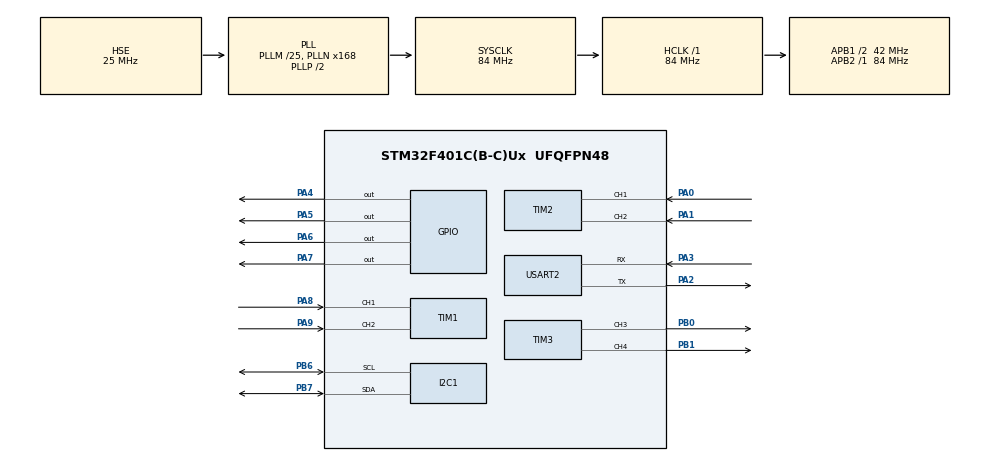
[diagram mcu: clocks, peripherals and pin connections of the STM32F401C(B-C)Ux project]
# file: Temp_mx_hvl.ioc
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Mcu.Family=STM32F4
Mcu.Name=STM32F401C(B-C)Ux
Mcu.Package=UFQFPN48
NVIC.PriorityGroup=NVIC_PRIORITYGROUP_2
NVIC.TIM4_IRQn=true\:2\:1\:true\:false\:true\:true\:true
NVIC.USART2_IRQn=true\:1\:1\:true\:false\:true\:true\:true
PA0-WKUP.Signal=S_TIM2_CH1_ETR
PA1.Signal=S_TIM2_CH2
PA13.Mode=Serial_Wire
PA13.Signal=SYS_JTMS-SWDIO
PA14.Mode=Serial_Wire
PA14.Signal=SYS_JTCK-SWCLK
PA2.Mode=Asynchronous
PA2.Signal=USART2_TX
PA3.Mode=Asynchronous
PA3.Signal=USART2_RX
PA4.GPIO_PuPd=GPIO_PULLUP
PA4.GPIO_Speed=GPIO_SPEED_FREQ_HIGH
PA4.Signal=GPIO_Output
PA5.GPIO_PuPd=GPIO_PULLUP
PA5.GPIO_Speed=GPIO_SPEED_FREQ_HIGH
PA5.Signal=GPIO_Output
PA6.GPIO_PuPd=GPIO_PULLUP
PA6.GPIO_Speed=GPIO_SPEED_FREQ_HIGH
PA6.Signal=GPIO_Output
PA7.GPIO_PuPd=GPIO_PULLUP
PA7.GPIO_Speed=GPIO_SPEED_FREQ_HIGH
PA7.Signal=GPIO_Output
PA8.Signal=S_TIM1_CH1
PA9.Signal=S_TIM1_CH2
PB0.Signal=S_TIM3_CH3
PB1.Signal=S_TIM3_CH4
PB6.Mode=I2C
PB6.Signal=I2C1_SCL
PB7.Mode=I2C
PB7.Signal=I2C1_SDA
PC14-OSC32_IN.Mode=LSE-External-Oscillator
PC14-OSC32_IN.Signal=RCC_OSC32_IN
PC15-OSC32_OUT.Mode=LSE-External-Oscillator
PC15-OSC32_OUT.Signal=RCC_OSC32_OUT
PH0\ -\ OSC_IN.Mode=HSE-External-Oscillator
PH0\ -\ OSC_IN.Signal=RCC_OSC_IN
PH1\ -\ OSC_OUT.Mode=HSE-External-Oscillator
PH1\ -\ OSC_OUT.Signal=RCC_OSC_OUT
ProjectManager.HeapSize=0x200
ProjectManager.StackSize=0x400
ProjectManager.TargetToolchain=MDK-ARM V5
RCC.48MHZClocksFreq_Value=42000000
RCC.AHBFreq_Value=84000000
RCC.APB1CLKDivider=RCC_HCLK_DIV2
RCC.APB1Freq_Value=42000000
RCC.APB1TimFreq_Value=84000000
RCC.APB2Freq_Value=84000000
RCC.APB2TimFreq_Value=84000000
RCC.CortexFreq_Value=84000000
RCC.HCLKFreq_Value=84000000
RCC.HSE_VALUE=25000000
RCC.HSI_VALUE=16000000
RCC.PLLM=25
RCC.PLLN=168
RCC.PLLSourceVirtual=RCC_PLLSOURCE_HSE
RCC.SYSCLKFreq_VALUE=84000000
RCC.SYSCLKSource=RCC_SYSCLKSOURCE_PLLCLK
RCC.VCOOutputFreq_Value=168000000
SH.S_TIM1_CH1.0=TIM1_CH1,Encoder_Interface
SH.S_TIM1_CH2.0=TIM1_CH2,Encoder_Interface
SH.S_TIM2_CH1_ETR.0=TIM2_CH1,Encoder_Interface
SH.S_TIM2_CH2.0=TIM2_CH2,Encoder_Interface
SH.S_TIM3_CH3.0=TIM3_CH3,PWM Generation3 CH3
SH.S_TIM3_CH4.0=TIM3_CH4,PWM Generation4 CH4
TIM3.Channel-PWM\ Generation3\ CH3=TIM_CHANNEL_3
TIM3.Channel-PWM\ Generation4\ CH4=TIM_CHANNEL_4
TIM4.AutoReloadPreload=TIM_AUTORELOAD_PRELOAD_ENABLE
TIM4.Period=100
TIM4.Prescaler=84
USART2.VirtualMode=VM_ASYNC
VP_TIM10_VS_ClockSourceINT.Mode=Enable_Timer
VP_TIM4_VS_ClockSourceINT.Mode=Internal
board=custom

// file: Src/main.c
/* USER CODE BEGIN Header */
/**
  ******************************************************************************
  * @file           : main.c
  * @brief          : Main program body
  ******************************************************************************
  * @attention
  *
  * <h2><center>&copy; Copyright (c) 2019 STMicroelectronics.
  * All rights reserved.</center></h2>
  *
  * This software component is licensed by ST under BSD 3-Clause license,
  * the "License"; You may not use this file except in compliance with the
  * License. You may obtain a copy of the License at:
  *                        opensource.org/licenses/BSD-3-Clause
  *
  ******************************************************************************
  */
/* USER CODE END Header */

#include "main.h"

/* USER CODE BEGIN PD */
#define USE_HAL_TIM_REGISTER_CALLBACKS 1
/* USER CODE END PD */

I2C_HandleTypeDef hi2c1;

TIM_HandleTypeDef htim1;
TIM_HandleTypeDef htim2;
TIM_HandleTypeDef htim3;
TIM_HandleTypeDef htim4;
TIM_HandleTypeDef htim10;

UART_HandleTypeDef huart2;

void SystemClock_Config(void);
static void MX_GPIO_Init(void);
void MX_TIM4_Init(void);
void MX_USART2_UART_Init(void);
static void MX_I2C1_Init(void);
static void MX_TIM1_Init(void);
static void MX_TIM2_Init(void);
static void MX_TIM3_Init(void);
static void MX_TIM10_Init(void);

int main(void)
{

  /* MCU Configuration--------------------------------------------------------*/

  /* Reset of all peripherals, Initializes the Flash interface and the Systick. */
  HAL_Init();

  /* Configure the system clock */
  SystemClock_Config();

  /* Initialize all configured peripherals */
  MX_GPIO_Init();
  MX_TIM4_Init();
  MX_USART2_UART_Init();
  MX_I2C1_Init();
  MX_TIM1_Init();
  MX_TIM2_Init();
  MX_TIM3_Init();
  MX_TIM10_Init();
  /* USER CODE BEGIN 2 */
  __HAL_TIM_ENABLE(&htim4);
  /* USER CODE END 2 */

  /* Infinite loop */
  while (1)
  {

  }
}

void SystemClock_Config(void)
{
  RCC_OscInitTypeDef RCC_OscInitStruct = {0};
  RCC_ClkInitTypeDef RCC_ClkInitStruct = {0};

  /** Configure the main internal regulator output voltage
  */
  __HAL_RCC_PWR_CLK_ENABLE();
  __HAL_PWR_VOLTAGESCALING_CONFIG(PWR_REGULATOR_VOLTAGE_SCALE2);
  /** Initializes the CPU, AHB and APB busses clocks
  */
  RCC_OscInitStruct.OscillatorType = RCC_OSCILLATORTYPE_HSE;
  RCC_OscInitStruct.HSEState = RCC_HSE_ON;
  RCC_OscInitStruct.PLL.PLLState = RCC_PLL_ON;
  RCC_OscInitStruct.PLL.PLLSource = RCC_PLLSOURCE_HSE;
  RCC_OscInitStruct.PLL.PLLM = 25;
  RCC_OscInitStruct.PLL.PLLN = 168;
  RCC_OscInitStruct.PLL.PLLP = RCC_PLLP_DIV2;
  RCC_OscInitStruct.PLL.PLLQ = 4;
  if (HAL_RCC_OscConfig(&RCC_OscInitStruct) != HAL_OK)
  {
    Error_Handler();
  }
  /** Initializes the CPU, AHB and APB busses clocks
  */
  RCC_ClkInitStruct.ClockType = RCC_CLOCKTYPE_HCLK|RCC_CLOCKTYPE_SYSCLK
                              |RCC_CLOCKTYPE_PCLK1|RCC_CLOCKTYPE_PCLK2;
  RCC_ClkInitStruct.SYSCLKSource = RCC_SYSCLKSOURCE_PLLCLK;
  RCC_ClkInitStruct.AHBCLKDivider = RCC_SYSCLK_DIV1;
  RCC_ClkInitStruct.APB1CLKDivider = RCC_HCLK_DIV2;
  RCC_ClkInitStruct.APB2CLKDivider = RCC_HCLK_DIV1;

  if (HAL_RCC_ClockConfig(&RCC_ClkInitStruct, FLASH_LATENCY_2) != HAL_OK)
  {
    Error_Handler();
  }
}

static void MX_I2C1_Init(void)
{

  hi2c1.Instance = I2C1;
  hi2c1.Init.ClockSpeed = 100000;
  hi2c1.Init.DutyCycle = I2C_DUTYCYCLE_2;
  hi2c1.Init.OwnAddress1 = 0;
  hi2c1.Init.AddressingMode = I2C_ADDRESSINGMODE_7BIT;
  hi2c1.Init.DualAddressMode = I2C_DUALADDRESS_DISABLE;
  hi2c1.Init.OwnAddress2 = 0;
  hi2c1.Init.GeneralCallMode = I2C_GENERALCALL_DISABLE;
  hi2c1.Init.NoStretchMode = I2C_NOSTRETCH_DISABLE;
  if (HAL_I2C_Init(&hi2c1) != HAL_OK)
  {
    Error_Handler();
  }

}

static void MX_TIM1_Init(void)
{

  TIM_Encoder_InitTypeDef sConfig = {0};
  TIM_MasterConfigTypeDef sMasterConfig = {0};

  htim1.Instance = TIM1;
  htim1.Init.Prescaler = 0;
  htim1.Init.CounterMode = TIM_COUNTERMODE_UP;
  htim1.Init.Period = 0;
  htim1.Init.ClockDivision = TIM_CLOCKDIVISION_DIV1;
  htim1.Init.RepetitionCounter = 0;
  htim1.Init.AutoReloadPreload = TIM_AUTORELOAD_PRELOAD_DISABLE;
  sConfig.EncoderMode = TIM_ENCODERMODE_TI1;
  sConfig.IC1Polarity = TIM_ICPOLARITY_RISING;
  sConfig.IC1Selection = TIM_ICSELECTION_DIRECTTI;
  sConfig.IC1Prescaler = TIM_ICPSC_DIV1;
  sConfig.IC1Filter = 0;
  sConfig.IC2Polarity = TIM_ICPOLARITY_RISING;
  sConfig.IC2Selection = TIM_ICSELECTION_DIRECTTI;
  sConfig.IC2Prescaler = TIM_ICPSC_DIV1;
  sConfig.IC2Filter = 0;
  if (HAL_TIM_Encoder_Init(&htim1, &sConfig) != HAL_OK)
  {
    Error_Handler();
  }
  sMasterConfig.MasterOutputTrigger = TIM_TRGO_RESET;
  sMasterConfig.MasterSlaveMode = TIM_MASTERSLAVEMODE_DISABLE;
  if (HAL_TIMEx_MasterConfigSynchronization(&htim1, &sMasterConfig) != HAL_OK)
  {
    Error_Handler();
  }

}

static void MX_TIM2_Init(void)
{

  TIM_Encoder_InitTypeDef sConfig = {0};
  TIM_MasterConfigTypeDef sMasterConfig = {0};

  htim2.Instance = TIM2;
  htim2.Init.Prescaler = 0;
  htim2.Init.CounterMode = TIM_COUNTERMODE_UP;
  htim2.Init.Period = 0;
  htim2.Init.ClockDivision = TIM_CLOCKDIVISION_DIV1;
  htim2.Init.AutoReloadPreload = TIM_AUTORELOAD_PRELOAD_DISABLE;
  sConfig.EncoderMode = TIM_ENCODERMODE_TI1;
  sConfig.IC1Polarity = TIM_ICPOLARITY_RISING;
  sConfig.IC1Selection = TIM_ICSELECTION_DIRECTTI;
  sConfig.IC1Prescaler = TIM_ICPSC_DIV1;
  sConfig.IC1Filter = 0;
  sConfig.IC2Polarity = TIM_ICPOLARITY_RISING;
  sConfig.IC2Selection = TIM_ICSELECTION_DIRECTTI;
  sConfig.IC2Prescaler = TIM_ICPSC_DIV1;
  sConfig.IC2Filter = 0;
  if (HAL_TIM_Encoder_Init(&htim2, &sConfig) != HAL_OK)
  {
    Error_Handler();
  }
  sMasterConfig.MasterOutputTrigger = TIM_TRGO_RESET;
  sMasterConfig.MasterSlaveMode = TIM_MASTERSLAVEMODE_DISABLE;
  if (HAL_TIMEx_MasterConfigSynchronization(&htim2, &sMasterConfig) != HAL_OK)
  {
    Error_Handler();
  }

}

static void MX_TIM3_Init(void)
{

  TIM_MasterConfigTypeDef sMasterConfig = {0};
  TIM_OC_InitTypeDef sConfigOC = {0};

  htim3.Instance = TIM3;
  htim3.Init.Prescaler = 0;
  htim3.Init.CounterMode = TIM_COUNTERMODE_UP;
  htim3.Init.Period = 0;
  htim3.Init.ClockDivision = TIM_CLOCKDIVISION_DIV1;
  htim3.Init.AutoReloadPreload = TIM_AUTORELOAD_PRELOAD_DISABLE;
  if (HAL_TIM_PWM_Init(&htim3) != HAL_OK)
  {
    Error_Handler();
  }
  sMasterConfig.MasterOutputTrigger = TIM_TRGO_RESET;
  sMasterConfig.MasterSlaveMode = TIM_MASTERSLAVEMODE_DISABLE;
  if (HAL_TIMEx_MasterConfigSynchronization(&htim3, &sMasterConfig) != HAL_OK)
  {
    Error_Handler();
  }
  sConfigOC.OCMode = TIM_OCMODE_PWM1;
  sConfigOC.Pulse = 0;
  sConfigOC.OCPolarity = TIM_OCPOLARITY_HIGH;
  sConfigOC.OCFastMode = TIM_OCFAST_DISABLE;
  if (HAL_TIM_PWM_ConfigChannel(&htim3, &sConfigOC, TIM_CHANNEL_3) != HAL_OK)
  {
    Error_Handler();
  }
  if (HAL_TIM_PWM_ConfigChannel(&htim3, &sConfigOC, TIM_CHANNEL_4) != HAL_OK)
  {
    Error_Handler();
  }
  HAL_TIM_MspPostInit(&htim3);

}

void MX_TIM4_Init(void)
{

  TIM_ClockConfigTypeDef sClockSourceConfig = {0};
  TIM_MasterConfigTypeDef sMasterConfig = {0};

  htim4.Instance = TIM4;
  htim4.Init.Prescaler = 84;
  htim4.Init.CounterMode = TIM_COUNTERMODE_UP;
  htim4.Init.Period = 100;
  htim4.Init.ClockDivision = TIM_CLOCKDIVISION_DIV1;
  htim4.Init.AutoReloadPreload = TIM_AUTORELOAD_PRELOAD_ENABLE;
  if (HAL_TIM_Base_Init(&htim4) != HAL_OK)
  {
    Error_Handler();
  }
  sClockSourceConfig.ClockSource = TIM_CLOCKSOURCE_INTERNAL;
  if (HAL_TIM_ConfigClockSource(&htim4, &sClockSourceConfig) != HAL_OK)
  {
    Error_Handler();
  }
  sMasterConfig.MasterOutputTrigger = TIM_TRGO_RESET;
  sMasterConfig.MasterSlaveMode = TIM_MASTERSLAVEMODE_DISABLE;
  if (HAL_TIMEx_MasterConfigSynchronization(&htim4, &sMasterConfig) != HAL_OK)
  {
    Error_Handler();
  }
  /* USER CODE BEGIN TIM4_Init 2 */
  __HAL_TIM_ENABLE_IT(&htim4, TIM_IT_UPDATE);
  /* USER CODE END TIM4_Init 2 */

}

static void MX_TIM10_Init(void)
{

  htim10.Instance = TIM10;
  htim10.Init.Prescaler = 0;
  htim10.Init.CounterMode = TIM_COUNTERMODE_UP;
  htim10.Init.Period = 0;
  htim10.Init.ClockDivision = TIM_CLOCKDIVISION_DIV1;
  htim10.Init.AutoReloadPreload = TIM_AUTORELOAD_PRELOAD_DISABLE;
  if (HAL_TIM_Base_Init(&htim10) != HAL_OK)
  {
    Error_Handler();
  }

}

void MX_USART2_UART_Init(void)
{

  huart2.Instance = USART2;
  huart2.Init.BaudRate = 115200;
  huart2.Init.WordLength = UART_WORDLENGTH_8B;
  huart2.Init.StopBits = UART_STOPBITS_1;
  huart2.Init.Parity = UART_PARITY_NONE;
  huart2.Init.Mode = UART_MODE_TX_RX;
  huart2.Init.HwFlowCtl = UART_HWCONTROL_NONE;
  huart2.Init.OverSampling = UART_OVERSAMPLING_16;
  if (HAL_UART_Init(&huart2) != HAL_OK)
  {
    Error_Handler();
  }

}

static void MX_GPIO_Init(void)
{
  GPIO_InitTypeDef GPIO_InitStruct = {0};

  /* GPIO Ports Clock Enable */
  __HAL_RCC_GPIOC_CLK_ENABLE();
  __HAL_RCC_GPIOH_CLK_ENABLE();
  __HAL_RCC_GPIOA_CLK_ENABLE();
  __HAL_RCC_GPIOB_CLK_ENABLE();

  /*Configure GPIO pin Output Level */
  HAL_GPIO_WritePin(GPIOA, GPIO_PIN_4|GPIO_PIN_5|GPIO_PIN_6|GPIO_PIN_7, GPIO_PIN_RESET);

  /*Configure GPIO pins : PA4 PA5 PA6 PA7 */
  GPIO_InitStruct.Pin = GPIO_PIN_4|GPIO_PIN_5|GPIO_PIN_6|GPIO_PIN_7;
  GPIO_InitStruct.Mode = GPIO_MODE_OUTPUT_PP;
  GPIO_InitStruct.Pull = GPIO_PULLUP;
  GPIO_InitStruct.Speed = GPIO_SPEED_FREQ_HIGH;
  HAL_GPIO_Init(GPIOA, &GPIO_InitStruct);

}

/* USER CODE BEGIN 4 */
void HVL_TIM_PeriodElapsedCallback(TIM_HandleTypeDef* htim){
  GPIOA->ODR ^= GPIO_PIN_4;
}
/* USER CODE END 4 */

void Error_Handler(void)
{
}

/************************ (C) COPYRIGHT STMicroelectronics *****END OF FILE****/
